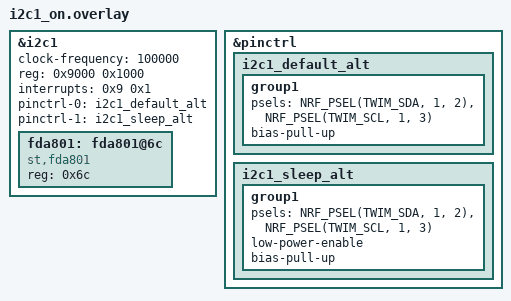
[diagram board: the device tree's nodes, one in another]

&i2c1 {
	status = "okay";
};

&pinctrl {
	i2c1_default_alt: i2c1_default_alt {
		group1 {
			psels = <NRF_PSEL(TWIM_SDA, 1, 2)>,
				<NRF_PSEL(TWIM_SCL, 1, 3)>;
			bias-pull-up;
		};
	};

	i2c1_sleep_alt: i2c1_sleep_alt {
		group1 {
			psels = <NRF_PSEL(TWIM_SDA, 1, 2)>,
				<NRF_PSEL(TWIM_SCL, 1, 3)>;
			low-power-enable;
			bias-pull-up;
		};
	};
};

&i2c1 {
	#address-cells = < 0x1 >;
	#size-cells = < 0x0 >;
	clock-frequency = < 100000 >;
	reg = < 0x9000 0x1000 >;
	interrupts = < 0x9 0x1 >;
	status = "okay";
	pinctrl-0 = <&i2c1_default_alt>;
	pinctrl-1 = <&i2c1_sleep_alt>;
	pinctrl-names = "default", "sleep";

	fda801: fda801@6c {
		compatible = "st,fda801";
		reg = <0x6c>;
	};
};
